AUTOSAR XML (schema 00046)
package /MICROSAR/WdgM_swc/DataTypes
  5 x impl type, all with category=TYPE_REFERENCE:
    WdgM_SupervisedEntityIdType: range raw 0..65535, implementation-data-type=uint16  # Identifier of a supervised entity
    WdgM_CheckpointIdType: range raw 0..65535, implementation-data-type=uint16  # Identifier of a checkpoint
    WdgM_ModeType: range raw 0..255, implementation-data-type=uint8  # Identifier of the Watchdog trigger mode
    WdgM_LocalStatusType: compu {0=WDGM_LOCAL_STATUS_OK, 1=WDGM_LOCAL_STATUS_FAILED, 2=WDGM_LOCAL_STATUS_EXPIRED, 4=WDGM_LOCAL_STATUS_DEACTIVATED}, range raw 0..4, implementation-data-type=uint8  # Local Monitoring Status of a supervised entity.
    WdgM_GlobalStatusType: compu {0=WDGM_GLOBAL_STATUS_OK, 1=WDGM_GLOBAL_STATUS_FAILED, 2=WDGM_GLOBAL_STATUS_EXPIRED, 3=WDGM_GLOBAL_STATUS_STOPPED, 4=WDGM_GLOBAL_STATUS_DEACTIVATED}, range raw 0..4, implementation-data-type=uint8  # Global Monitoring Status summarizes all local monitoring statuses of all supervised entities.
package /MICROSAR/WdgM_swc/Interfaces
  5 x client server interface, all with is-service=true, service-kind=WATCH-DOG-MANAGER:
    WdgM_AliveSupervision
      operation CheckpointReached: possible-error=WdgM_AliveSupervision/E_NOT_OK  # Indicates to the Watchdog Manager that a Checkpoint within a Supervised Entity has been reached.
        arg CPID: type=WdgM_CheckpointIdType, direction=IN  # Identifier of the checkpoint within a supervised entity that has been reached.
      error E_NOT_OK: error-code=1
    WdgM_LocalStatus
      operation GetLocalStatus: possible-error=WdgM_LocalStatus/E_NOT_OK  # Returns the supervision status of a supervised entity.
        arg Status: type=WdgM_LocalStatusType, direction=OUT  # Supervision status of the given supervised entity.
      error E_NOT_OK: error-code=1
    WdgM_General
      6 x operation, all with possible-error=WdgM_General/E_NOT_OK:
        GetMode  # Returns the current mode of the Watchdog Manager.
          arg Mode: type=WdgM_ModeType, direction=OUT  # Current mode of the Watchdog Manager.
        GetGlobalStatus  # Returns the global supervision status of the Watchdog Manager.
          arg Status: type=WdgM_GlobalStatusType, direction=OUT  # Global supervision status of the Watchdog Manager.
        GetLocalStatus  # Returns the supervision status of a supervised entity.
          arg SEID: type=WdgM_SupervisedEntityIdType, direction=IN  # Identifier of the supervised entity whose supervision status shall be returned.
          arg Status: type=WdgM_LocalStatusType, direction=OUT  # Supervision status of the given supervised entity.
        PerformReset  # Instructs the Watchdog Manager to cause a watchdog reset.
        SetMode  # Requests a new trigger mode
          arg Mode: type=WdgM_ModeType, direction=IN  # Desired new trigger mode id.
          arg CallerID: type=uint16, direction=IN  # Module ID of the calling module.
        GetFirstExpiredSEID  # Returns the id of that supervised entity which first reached the status WDGM_LOCAL_STATUS_EXPIRED.
          arg SEID: type=WdgM_SupervisedEntityIdType, direction=OUT  # Pointer to a variable that stores the id of the supervised entity.
      error E_NOT_OK: error-code=1
    WdgM_LocalStatusCallback
      operation LocalStatusCallback  # Callback function that will be invoked if the local supervision status has changed.
        arg Status: type=WdgM_LocalStatusType, direction=IN  # Local supervision status after the local supervision status of the related supervised entity has changed.
    WdgM_GlobalStatusCallback
      operation GlobalStatusCallback  # Callback function that will be invoked if the global supervision status has changed.
        arg Status: type=WdgM_GlobalStatusType, direction=IN  # Global supervision status after the global supervision status has changed.
package /MICROSAR/WdgM_swc/ComponentTypes
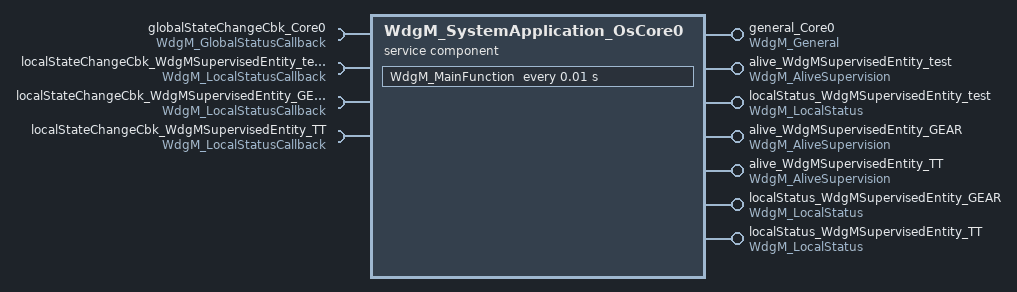
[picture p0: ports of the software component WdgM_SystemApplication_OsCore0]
  service sw component type WdgM_SystemApplication_OsCore0: category=SERVICE_COMPONENT
    provide port general_Core0: provided-interface=WdgM_General  # General P-Port-Prototype for core 0 (SystemApplication_OsCore0)
    provide port alive_WdgMSupervisedEntity_test: provided-interface=WdgM_AliveSupervision  # Alive-P-Port Prototype for supervised entity 'WdgMSupervisedEntity_test' with Id '0' for Application 'SystemApplication_OsCore0'.
    provide port localStatus_WdgMSupervisedEntity_test: provided-interface=WdgM_LocalStatus  # P-Port Prototype for supervised entity 'WdgMSupervisedEntity_test' with Id '0' for Application 'SystemApplication_OsCore0' to request the local status.
    require port globalStateChangeCbk_Core0: required-interface=WdgM_GlobalStatusCallback  # Global-Status-Callback-R-Port Prototype for core 0 ('SystemApplication_OsCore0')
    require port localStateChangeCbk_WdgMSupervisedEntity_test: required-interface=WdgM_LocalStatusCallback  # Local-Status-Callback-R-Port Prototype for supervised entity 'WdgMSupervisedEntity_test' with Id '0' for Application 'SystemApplication_OsCore0'.
    4 x provide port:
      alive_WdgMSupervisedEntity_GEAR: provided-interface=WdgM_AliveSupervision  # Alive-P-Port Prototype for supervised entity 'WdgMSupervisedEntity_GEAR' with Id '1' for Application 'SystemApplication_OsCore0'.
      alive_WdgMSupervisedEntity_TT: provided-interface=WdgM_AliveSupervision  # Alive-P-Port Prototype for supervised entity 'WdgMSupervisedEntity_TT' with Id '2' for Application 'SystemApplication_OsCore0'.
      localStatus_WdgMSupervisedEntity_GEAR: provided-interface=WdgM_LocalStatus  # P-Port Prototype for supervised entity 'WdgMSupervisedEntity_GEAR' with Id '1' for Application 'SystemApplication_OsCore0' to request the local status.
      localStatus_WdgMSupervisedEntity_TT: provided-interface=WdgM_LocalStatus  # P-Port Prototype for supervised entity 'WdgMSupervisedEntity_TT' with Id '2' for Application 'SystemApplication_OsCore0' to request the local status.
    require port localStateChangeCbk_WdgMSupervisedEntity_GEAR: required-interface=WdgM_LocalStatusCallback  # Local-Status-Callback-R-Port Prototype for supervised entity 'WdgMSupervisedEntity_GEAR' with Id '1' for Application 'SystemApplication_OsCore0'.
    require port localStateChangeCbk_WdgMSupervisedEntity_TT: required-interface=WdgM_LocalStatusCallback  # Local-Status-Callback-R-Port Prototype for supervised entity 'WdgMSupervisedEntity_TT' with Id '2' for Application 'SystemApplication_OsCore0'.
    behavior WdgM_SystemApplication_OsCore0InternalBehavior: handle-termination-and-restart=NO-SUPPORT
      timing event Timer_WdgM_MainFunction: start-on-event=WdgM_MainFunction, period=0.01
      12 x operation invoked event:
        OpEventGetMode_GetMode_general_Core0: start-on-event=GetMode, operation=general_Core0.GetMode
        OpEventGetGlobalStatus_GetGlobalStatus_general_Core0: start-on-event=GetGlobalStatus, operation=general_Core0.GetGlobalStatus
        OpEventGetLocalStatus_GetLocalStatus_general_Core0: start-on-event=GetLocalStatus, operation=general_Core0.GetLocalStatus
        OpEventPerformReset_PerformReset_general_Core0: start-on-event=PerformReset, operation=general_Core0.PerformReset
        OpEventSetMode_SetMode_general_Core0: start-on-event=SetMode, operation=general_Core0.SetMode
        OpEventGetFirstExpiredSEID_GetFirstExpiredSEID_general_Core0: start-on-event=GetFirstExpiredSEID, operation=general_Core0.GetFirstExpiredSEID
        OpEventCheckpointReached_CheckpointReached_alive_WdgMSupervisedEntity_test: start-on-event=CheckpointReached, operation=alive_WdgMSupervisedEntity_test.CheckpointReached
        OpEventGetLocalStatus_GetLocalStatus_localStatus_WdgMSupervisedEntity_test: start-on-event=GetLocalStatus, operation=localStatus_WdgMSupervisedEntity_test.GetLocalStatus
        OpEventCheckpointReached_CheckpointReached_alive_WdgMSupervisedEntity_GEAR: start-on-event=CheckpointReached, operation=alive_WdgMSupervisedEntity_GEAR.CheckpointReached
        OpEventCheckpointReached_CheckpointReached_alive_WdgMSupervisedEntity_TT: start-on-event=CheckpointReached, operation=alive_WdgMSupervisedEntity_TT.CheckpointReached
        OpEventGetLocalStatus_GetLocalStatus_localStatus_WdgMSupervisedEntity_GEAR: start-on-event=GetLocalStatus, operation=localStatus_WdgMSupervisedEntity_GEAR.GetLocalStatus
        OpEventGetLocalStatus_GetLocalStatus_localStatus_WdgMSupervisedEntity_TT: start-on-event=GetLocalStatus, operation=localStatus_WdgMSupervisedEntity_TT.GetLocalStatus
      port-api-options:
        {enable-take-address=true, indirect-api=false, port-defined-argument-value{value=SEID:0, value-type=WdgM_SupervisedEntityIdType}, port=alive_WdgMSupervisedEntity_test}
        {enable-take-address=true, indirect-api=false, port-defined-argument-value{value=0, value-type=WdgM_SupervisedEntityIdType}, port=localStatus_WdgMSupervisedEntity_test}
        enable-take-address=true, indirect-api=false, port=general_Core0
        enable-take-address=true, indirect-api=false, port=globalStateChangeCbk_Core0
        enable-take-address=true, indirect-api=false, port=localStateChangeCbk_WdgMSupervisedEntity_test
        {enable-take-address=true, indirect-api=false, port-defined-argument-value{value=SEID:1, value-type=WdgM_SupervisedEntityIdType}, port=alive_WdgMSupervisedEntity_GEAR}
        {enable-take-address=true, indirect-api=false, port-defined-argument-value{value=SEID:2, value-type=WdgM_SupervisedEntityIdType}, port=alive_WdgMSupervisedEntity_TT}
        {enable-take-address=true, indirect-api=false, port-defined-argument-value{value=1, value-type=WdgM_SupervisedEntityIdType}, port=localStatus_WdgMSupervisedEntity_GEAR}
        {enable-take-address=true, indirect-api=false, port-defined-argument-value{value=2, value-type=WdgM_SupervisedEntityIdType}, port=localStatus_WdgMSupervisedEntity_TT}
        enable-take-address=true, indirect-api=false, port=localStateChangeCbk_WdgMSupervisedEntity_GEAR
        enable-take-address=true, indirect-api=false, port=localStateChangeCbk_WdgMSupervisedEntity_TT
      8 x runnable, all with can-be-invoked-concurrently=true:
        WdgM_MainFunction
          4 x sync call, all with timeout=0:
            OpServerCallWdgM_MainFunction_GlobalStatusCallback_globalStateChangeCbk_Core0: operation=globalStateChangeCbk_Core0.GlobalStatusCallback
            OpServerCallWdgM_MainFunction_LocalStatusCallback_localStateChangeCbk_WdgMSupervisedEntity_test: operation=localStateChangeCbk_WdgMSupervisedEntity_test.LocalStatusCallback
            OpServerCallWdgM_MainFunction_LocalStatusCallback_localStateChangeCbk_WdgMSupervisedEntity_GEAR: operation=localStateChangeCbk_WdgMSupervisedEntity_GEAR.LocalStatusCallback
            OpServerCallWdgM_MainFunction_LocalStatusCallback_localStateChangeCbk_WdgMSupervisedEntity_TT: operation=localStateChangeCbk_WdgMSupervisedEntity_TT.LocalStatusCallback
        GetMode: symbol=WdgM_GetMode
        GetGlobalStatus: symbol=WdgM_GetGlobalStatus
        GetLocalStatus: symbol=WdgM_GetLocalStatus
        PerformReset: symbol=WdgM_PerformReset
        SetMode: symbol=WdgM_SetMode
        GetFirstExpiredSEID: symbol=WdgM_GetFirstExpiredSEID
        CheckpointReached: symbol=WdgM_CheckpointReached
  swc implementation WdgM_SystemApplication_OsCore0Implementation: programming-language=C, behavior=WdgM_SystemApplication_OsCore0InternalBehavior
